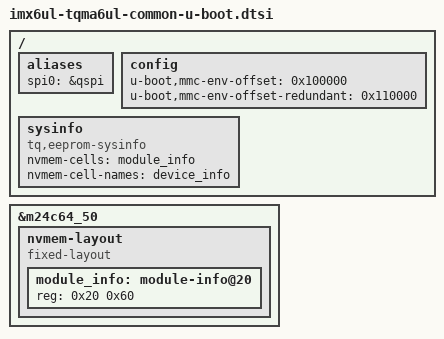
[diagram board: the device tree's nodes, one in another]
// SPDX-License-Identifier: (GPL-2.0-or-later OR MIT)
/*
 * Copyright (c) 2024-2026 TQ-Systems GmbH <u-boot@ew.tq-group.com>,
 * D-82229 Seefeld, Germany.
 * Author: Max Merchel
 */

/ {
	aliases {
		spi0 = &qspi;
	};

	config {
		u-boot,mmc-env-offset = <0x100000>;
		u-boot,mmc-env-offset-redundant = <0x110000>;
	};

	sysinfo: sysinfo {
		compatible = "tq,eeprom-sysinfo";
		nvmem-cells = <&module_info>;
		nvmem-cell-names = "device_info";
	};
};

&m24c64_50 {
	nvmem-layout {
		compatible = "fixed-layout";
		#address-cells = <1>;
		#size-cells = <1>;

		module_info: module-info@20 {
			reg = <0x20 0x60>;
		};
	};
};
